# max32570 register map
Vendor: Maxim-Integrated; Series: ARMCM4; File version: 1.0
CPU: CM4 r2p1, little endian, MPU, FPU, 3 interrupt priority bits
Registers are 32-bit, read-write, reset 0x0 unless marked. A register's access mark holds for its fields unless they carry their own. Offsets are from the block's base; [hi:lo] are bit positions; {n}, {i} and the like mark numbered series; 'fields as' and 'values as' point back to an identical list.

## AES — AES Keys.
Base 0x40005000
0x00 AES_SRAM_KEY
0x80 AES_CODE_KEY
0x100 AES_DATA_KEY

## CAMERAIF — Parallel Camera Interface.
Base 0x4000E000
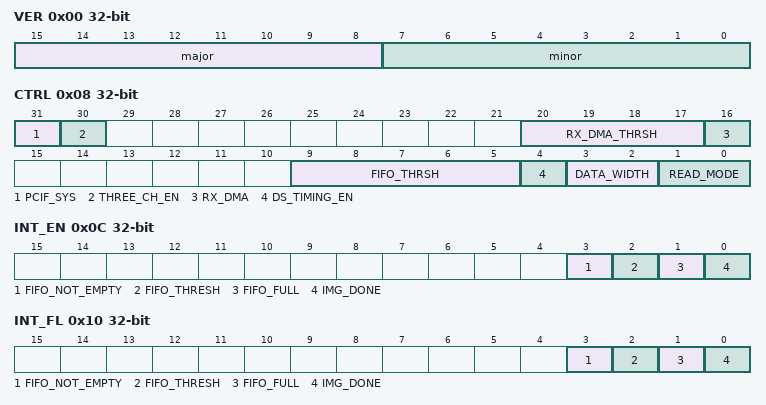
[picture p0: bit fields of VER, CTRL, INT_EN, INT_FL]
0x00 VER — Hardware Version.
  [15:8] major — Major Version Number.
  [7:0] minor — Minor Version Number.
0x04 FIFO_SIZE — FIFO Depth.
  [7:0] fifo_size
0x08 CTRL — Control Register.
  [31] PCIF_SYS — PCIF Control.
    0=dis (PCIF disabled.); 1=en (PCIF enabled.)
  [30] THREE_CH_EN — Three-channel mode enable.
  [20:17] RX_DMA_THRSH — DMA Threshold.
  [16] RX_DMA — DMA Enable.
    0=dis (DMA disabled.); 1=en (DMA enabled.)
  [9:5] FIFO_THRSH — Data FIFO Threshold.
  [4] DS_TIMING_EN — DS Timing Enable.
    0=dis (Timing from VSYNC and HSYNC.); 1=en (Timing embedded in data using SAV and EAV codes.)
  [3:2] DATA_WIDTH
    0=8bit; 1=10bit; 2=12bit
  [1:0] READ_MODE
    0=dis (Camera Interface Disabled.); 1=single_img (Single Image Capture.); 2=Continuous Image Capture
0x0C INT_EN — Interupt Enable Register.
  [3] FIFO_NOT_EMPTY
  [2] FIFO_THRESH — FIFO Threshold Level Met.
  [1] FIFO_FULL
  [0] IMG_DONE — Image Done.
0x10 INT_FL — Interupt Flag Register.
  fields as INT_EN
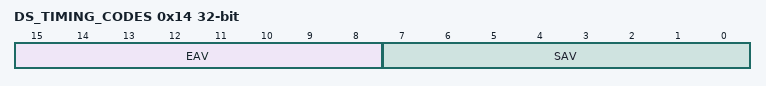
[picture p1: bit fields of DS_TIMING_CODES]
0x14 DS_TIMING_CODES — DS Timing Code Register.
  [15:8] EAV — End Active Video Code.
  [7:0] SAV — Start Active Video Code.
0x30 FIFO_DATA
  [31:0] DATA — Data from FIFO to be read by DMA.

## CLCD — Color LCD Controller
Base 0x40031000
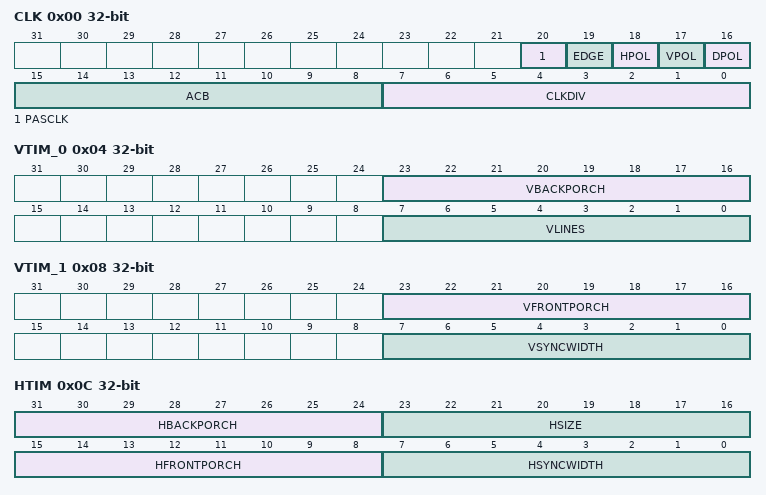
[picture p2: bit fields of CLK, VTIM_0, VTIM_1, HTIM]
0x00 CLK — LCD Clock Control Register
  [20] PASCLK — Clock Active on Data
    0=ALWAYSACTIVE; 1=ACTIVEONDATA
  [19] EDGE — Edge Selection
    0=RISEEDGE (Rising edge); 1=FALLEDGE (Falling Edge)
  [18] HPOL — H Polarity
    1=ACTIVEHI; 0=ACTIVELO (Active Low)
  [17] VPOL — V Polarity
    1=ACTIVEHI; 0=ACTIVELO (Active Low)
  [16] DPOL — D Polarity
    0=ACTIVEHI; 1=ACTIVELO (Active Low)
  [15:8] ACB
  [7:0] CLKDIV — Clock divsor
0x04 VTIM_0 — LCD Vertical Timing 0 Register
  [23:16] VBACKPORCH, [7:0] VLINES
0x08 VTIM_1 — LCD Vertical Timing 1 Register
  [23:16] VFRONTPORCH, [7:0] VSYNCWIDTH
0x0C HTIM — LCD Horizontal Timing Register.
  [31:24] HBACKPORCH — Horizontal Back Porch size in CLCD Clocks from 1 to 256 -> HBP= (HBACKPORCH+1)
  [23:16] HSIZE — Horizontal Front Porch Size in Pixels = (HSIZE + 1) *16
  [15:8] HFRONTPORCH — Horizontal Front Porch size in lines from 1 to 256
  [7:0] HSYNCWIDTH — Horizontal Sync Width in CLCD Clocks from 1 to 256 HSync Width = HSYNCWIDTH+1 Clocks
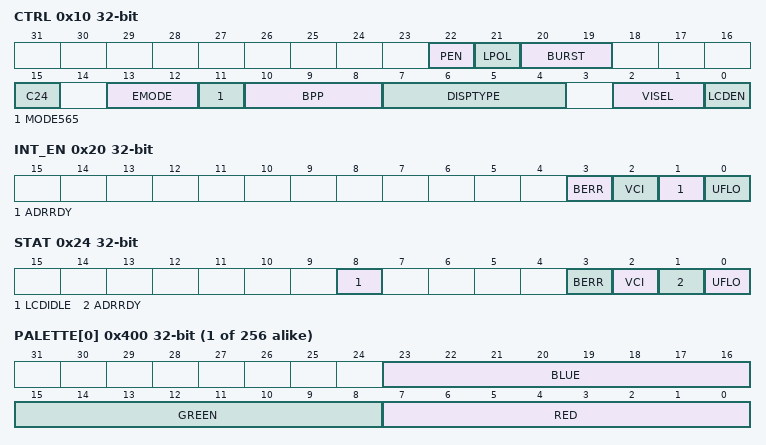
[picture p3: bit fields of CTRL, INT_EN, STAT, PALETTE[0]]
0x10 CTRL — LCD Control Register
  [22] PEN
  [21] LPOL
    0=ACTIVEHI (ACTIVE HIGH); 1=ACTIVELO (ACTIVE LOW)
  [20:19] BURST
    0=WORDS4; 1=WORDS8
  [15] C24
  [13:12] EMODE
    0=LLBP; 1=BBBP; 2=LBBP
  [11] MODE565
    0=BGR556 (MODE 556); 1=RGB565 (MODE 565)
  [10:8] BPP
    0=BPP1; 1=BPP2; 2=BPP4; 3=BPP8; 4=BPP16; 5=BPP24
  [7:4] DISPTYPE — Display Type
    4=STNCOLOR8BIT; 8=CLCD
  [2:1] VISEL — VI Select
    0=ONVERTSYNC (On Vertical Sync); 1=ONVERTBACKPORCH (On Vertical Back Porch); 2=ONACTIVEVIDEO; 3=ONVERTFRONTPORCH (On Vertical Front Porch)
  [0] LCDEN — LCD Enable
    0=DISABLE; 1=ENABLE
0x18 FR — FRBUF
0x20 INT_EN — LCD Interrupt Enable Register.
  [3] BERR — BERR Interupt Enable
  [2] VCI — VCI Interupt Enable
  [1] ADRRDY — Address Ready Interupt Enable
  [0] UFLO — Under FLow Interupt Enable
0x24 STAT write-1-clears — LCD Status Register.
  [8] LCDIDLE — LCD IDLE Staus
    0=BUSY; 1=READY
  [3] BERR — BERR Interupt Status
    on read: 0=Inactive (No interrupt pending); 1=Pending (Interrupt pending) | on write: 1=Clears the interrupt flag
  [2] VCI — VCI Interupt Status
    values as BERR
  [1] ADRRDY — Address Ready Interupt Status
    values as BERR
  [0] UFLO — Under FLow Interupt Status
    values as BERR
{0x400+4i} PALETTE[{i}] (i=0..255)
  [23:16] BLUE — Blue Data for Pallet Entry.
  [15:8] GREEN — Green Data for Pallet Entry.
  [7:0] RED — Red Data for Pallet Entry.
